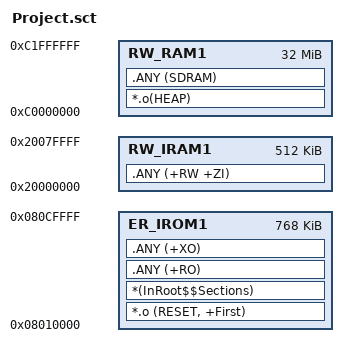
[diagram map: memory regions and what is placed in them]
; *************************************************************
; *** Scatter-Loading Description File generated by uVision ***
; *************************************************************

LR_IROM1 0x08010000 0x000C0000  {    ; load region size_region   0x08010000
  ER_IROM1 0x08010000 0x000C0000  {  ; load address = execution address
   *.o (RESET, +First)
   *(InRoot$$Sections)
   .ANY (+RO)
   .ANY (+XO)
  }
  RW_RAM1 0xC0000000 0x02000000  {  ; RW data
   *.o(HEAP)
   .ANY (SDRAM)
  }
  RW_IRAM1 0x20000000 0x00080000  {
   .ANY (+RW +ZI)
  }
}

